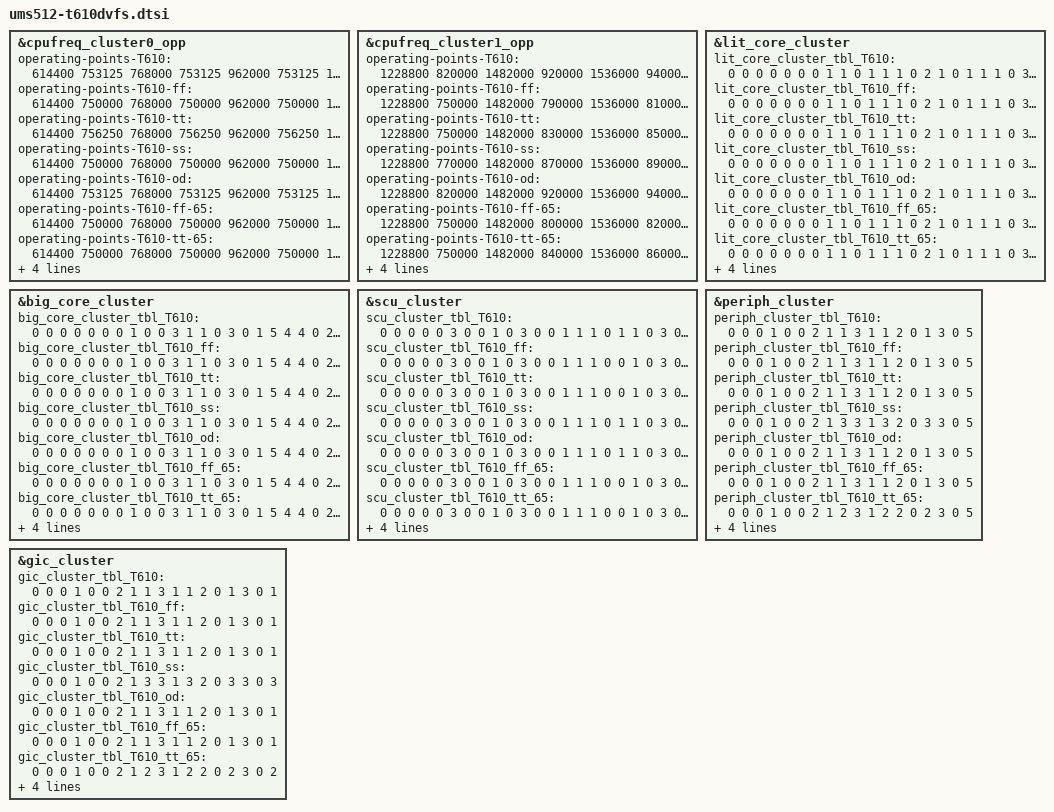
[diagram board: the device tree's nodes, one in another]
// SPDX-License-Identifier: (GPL-2.0+ OR MIT)
/*
 * Unisoc Sharkl5Pro platform T610 SOC DVFS DTS file
 *
 * Copyright (C) 2019, Unisoc Communications Inc.
 */

#include "sharkl5Pro.dtsi"
#include "ums512.dtsi"

&cpufreq_cluster0_opp {
	/* operating-points-T610-0-0
	 * v0/v1-soc_ver 0-binning 0-temp
	 * v0-T618 v1-T610
	 */
	operating-points-T610 = <
		/* kHZ   uV */
		614400  753125
		768000  753125
		962000  753125
		1144000 815625
		1228800 846875
		1482000 934375
		1536000 953125
		1716000 1015625
		1820000 1050000
	>;

	operating-points-T610-ff = <
		/* kHZ   uV */
		614400  750000
		768000  750000
		962000  750000
		1144000 750000
		1228800 750000
		1482000 803125
		1536000 821875
		1716000 884375
		1820000 921875
	>;

	operating-points-T610-tt = <
		/* kHZ   uV */
		614400  756250
		768000  756250
		962000  756250
		1144000 756250
		1228800 756250
		1482000 843750
		1536000 862500
		1716000 925000
		1820000 962500
	>;

	operating-points-T610-ss = <
		/* kHZ   uV */
		614400  750000
		768000  750000
		962000  750000
		1144000 765625
		1228800 796875
		1482000 884375
		1536000 903125
		1716000 965625
		1820000 1000000
	>;

	operating-points-T610-od = <
		/* kHZ   uV */
		614400  753125
		768000  753125
		962000  753125
		1144000 815625
		1228800 846875
		1482000 934375
		1536000 953125
		1716000 1015625
		1820000 1050000
	>;

	operating-points-T610-ff-65 = <
		/* kHZ   uV */
		614400  750000
		768000  750000
		962000  750000
		1144000 750000
		1228800 750000
		1482000 812500
		1536000 834375
		1716000 903125
		1820000 940625
	>;

	operating-points-T610-tt-65 = <
		/* kHZ   uV */
		614400  750000
		768000  750000
		962000  750000
		1144000 750000
		1228800 759375
		1482000 856250
		1536000 875000
		1716000 943750
		1820000 981250
	>;

	operating-points-T610-ss-65 = <
		/* kHZ   uV */
		614400  750000
		768000  750000
		962000  750000
		1144000 771875
		1228800 803125
		1482000 896875
		1536000 915625
		1716000 984375
		1820000 1021875
	>;

	operating-points-T610-od-65 = <
		/* kHZ   uV */
		614400  756250
		768000  756250
		962000  756250
		1144000 821875
		1228800 853125
		1482000 946875
		1536000 965625
		1716000 1034375
	>;
};

&cpufreq_cluster1_opp {
	operating-points-T610 = <
		/* kHZ   uV */
		1228800	 820000
		1482000	 920000
		1536000	 940000
		1742000  1020000
		1820000  1050000
	>;

	operating-points-T610-ff = <
		/* kHZ   uV */
		1228800	 750000
		1482000	 790000
		1536000	 810000
		1742000  890000
		1820000  920000
	>;

	operating-points-T610-tt = <
		/* kHZ   uV */
		1228800	 750000
		1482000	 830000
		1536000	 850000
		1742000  930000
		1820000  960000
	>;

	operating-points-T610-ss = <
		/* kHZ   uV */
		1228800	 770000
		1482000	 870000
		1536000	 890000
		1742000  970000
		1820000  1000000
	>;

	operating-points-T610-od = <
		/* kHZ   uV */
		1228800	 820000
		1482000	 920000
		1536000	 940000
		1742000  1020000
		1820000  1050000
	>;

	operating-points-T610-ff-65 = <
		/* kHZ   uV */
		1228800	 750000
		1482000	 800000
		1536000	 820000
		1742000  910000
		1820000  940000
	>;

	operating-points-T610-tt-65 = <
		/* kHZ   uV */
		1228800	 750000
		1482000	 840000
		1536000	 860000
		1742000  950000
		1820000  980000
	>;

	operating-points-T610-ss-65 = <
		/* kHZ   uV */
		1228800	 770000
		1482000	 880000
		1536000	 900000
		1742000  990000
		1820000  1020000
	>;

	operating-points-T610-od-65 = <
		/* kHZ   uV */
		1228800	 830000
		1482000	 930000
		1536000	 960000
		1742000  1040000
	>;
};

&lit_core_cluster{
	/* lit-core-dvfs-tbl-v1-0-0
	 * v0/v1-soc_ver v0-T618 v1-T610 0-binning 0-temp
	 * sel, div, vol, vote_scu, vote_peri, vote_gic, mpllx
	 */
	lit_core_cluster_tbl_T610 = <
		0 0 0 0 0 0 0
		1 1 0 1 1 1 0
		2 1 0 1 1 1 0
		3 0 0 2 1 1 0
		3 0 1 3 1 1 1
		1 0 2 4 1 1 0
		3 0 3 5 4 4 2
		2 0 4 6 4 4 0
		3 0 5 7 4 5 3
		3 0 6 8 4 5 4
		3 0 6 8 4 5 4
	>;

	lit_core_cluster_tbl_T610_ff = <
		0 0 0 0 0 0 0
		1 1 0 1 1 1 0
		2 1 0 1 1 1 0
		3 0 0 2 1 1 0
		3 0 0 3 1 1 1
		1 0 0 4 1 1 0
		3 0 1 5 4 4 2
		2 0 2 6 4 4 0
		3 0 3 7 4 5 3
		3 0 4 8 4 5 4
		3 0 4 8 4 5 4
	>;

	lit_core_cluster_tbl_T610_tt = <
		0 0 0 0 0 0 0
		1 1 0 1 1 1 0
		2 1 0 1 1 1 0
		3 0 0 2 1 1 0
		3 0 0 3 1 1 1
		1 0 0 4 1 1 0
		3 0 1 5 4 4 2
		2 0 2 6 4 4 0
		3 0 3 7 4 5 3
		3 0 4 8 4 5 4
		3 0 4 8 4 5 4
	>;

	lit_core_cluster_tbl_T610_ss = <
		0 0 0 0 0 0 0
		1 1 0 1 1 1 0
		2 1 0 1 1 1 0
		3 0 0 2 1 1 0
		3 0 1 3 1 1 1
		1 0 2 4 1 1 0
		3 0 3 5 4 4 2
		2 0 4 6 4 4 0
		3 0 5 7 4 5 3
		3 0 6 8 4 5 4
		3 0 6 8 4 5 4
	>;

	lit_core_cluster_tbl_T610_od = <
		0 0 0 0 0 0 0
		1 1 0 1 1 1 0
		2 1 0 1 1 1 0
		3 0 0 2 1 1 0
		3 0 1 3 1 1 1
		1 0 2 4 1 1 0
		3 0 3 5 4 4 2
		2 0 4 6 4 4 0
		3 0 5 7 4 5 3
		3 0 6 8 4 5 4
		3 0 6 8 4 5 4
	>;

	lit_core_cluster_tbl_T610_ff_65 = <
		0 0 0 0 0 0 0
		1 1 0 1 1 1 0
		2 1 0 1 1 1 0
		3 0 0 2 1 1 0
		3 0 0 3 1 1 1
		1 0 0 4 1 1 0
		3 0 1 5 4 4 2
		2 0 2 6 4 4 0
		3 0 3 7 4 5 3
		3 0 4 8 4 5 4
		3 0 4 8 4 5 4
	>;

	lit_core_cluster_tbl_T610_tt_65 = <
		0 0 0 0 0 0 0
		1 1 0 1 1 1 0
		2 1 0 1 1 1 0
		3 0 0 2 1 1 0
		3 0 0 3 1 1 1
		1 0 1 4 1 1 0
		3 0 2 5 4 4 2
		2 0 3 6 4 4 0
		3 0 4 7 4 5 3
		3 0 5 8 4 5 4
		3 0 5 8 4 5 4
	>;

	lit_core_cluster_tbl_T610_ss_65 = <
		0 0 0 0 0 0 0
		1 1 0 1 1 1 0
		2 1 0 1 1 1 0
		3 0 0 2 1 1 0
		3 0 1 3 1 1 1
		1 0 2 4 1 1 0
		3 0 3 5 4 4 2
		2 0 4 6 4 4 0
		3 0 5 7 4 5 3
		3 0 6 8 4 5 4
		3 0 6 8 4 5 4
	>;

	lit_core_cluster_tbl_T610_od_65 = <
		0 0 0 0 0 0 0
		1 1 0 1 1 1 0
		2 1 0 1 1 1 0
		3 0 0 2 1 1 0
		3 0 1 3 1 1 1
		1 0 2 4 1 1 0
		3 0 3 5 4 4 2
		2 0 4 6 4 4 0
		3 0 5 7 4 5 3
		3 0 5 7 4 5 3
		3 0 5 7 4 5 3
	>;
};

&big_core_cluster {
	/* sel, div, vol, vote_scu, vote_peri, vote_gic, mpllx */
	big_core_cluster_tbl_T610 = <
		0 0 0 0 0 0 0
		1 0 0 3 1 1 0
		3 0 1 5 4 4 0
		2 0 2 6 4 4 0
		3 0 3 7 4 5 1
		3 0 4 8 4 5 2
		3 0 4 8 4 5 2
	>;

	big_core_cluster_tbl_T610_ff = <
		0 0 0 0 0 0 0
		1 0 0 3 1 1 0
		3 0 1 5 4 4 0
		2 0 2 6 4 4 0
		3 0 3 7 4 5 1
		3 0 4 8 4 5 2
		3 0 4 8 4 5 2
	>;

	big_core_cluster_tbl_T610_tt = <
		0 0 0 0 0 0 0
		1 0 0 3 1 1 0
		3 0 1 5 4 4 0
		2 0 2 6 4 4 0
		3 0 3 7 4 5 1
		3 0 4 8 4 5 2
		3 0 4 8 4 5 2
	>;

	big_core_cluster_tbl_T610_ss = <
		0 0 0 0 0 0 0
		1 0 0 3 1 1 0
		3 0 1 5 4 4 0
		2 0 2 6 4 4 0
		3 0 3 7 4 5 1
		3 0 4 8 4 5 2
		3 0 4 8 4 5 2
	>;

	big_core_cluster_tbl_T610_od = <
		0 0 0 0 0 0 0
		1 0 0 3 1 1 0
		3 0 1 5 4 4 0
		2 0 2 6 4 4 0
		3 0 3 7 4 5 1
		3 0 4 8 4 5 2
		3 0 4 8 4 5 2
	>;

	big_core_cluster_tbl_T610_ff_65 = <
		0 0 0 0 0 0 0
		1 0 0 3 1 1 0
		3 0 1 5 4 4 0
		2 0 2 6 4 4 0
		3 0 3 7 4 5 1
		3 0 4 8 4 5 2
		3 0 4 8 4 5 2
	>;

	big_core_cluster_tbl_T610_tt_65 = <
		0 0 0 0 0 0 0
		1 0 0 3 1 1 0
		3 0 1 5 4 4 0
		2 0 2 6 4 4 0
		3 0 3 7 4 5 1
		3 0 4 8 4 5 2
		3 0 4 8 4 5 2
	>;

	big_core_cluster_tbl_T610_ss_65 = <
		0 0 0 0 0 0 0
		1 0 0 3 1 1 0
		3 0 1 5 4 4 0
		2 0 2 6 4 4 0
		3 0 3 7 4 5 1
		3 0 4 8 4 5 2
		3 0 4 8 4 5 2
	>;

	big_core_cluster_tbl_T610_od_65 = <
		0 0 0 0 0 0 0
		1 0 0 3 1 1 0
		3 0 1 5 4 4 0
		2 0 2 6 4 4 0
		3 0 3 7 4 5 1
		3 0 3 7 4 5 1
		3 0 3 7 4 5 1
	>;
};

&scu_cluster {
	/* sel div vol ace_div mpllx */
	scu_cluster_tbl_T610 = <
		0 0 0 0 0
		3 0 0 1 0
		3 0 0 1 1
		1 0 1 1 0
		3 0 2 1 2
		3 0 3 1 3
		3 0 4 1 4
		3 0 5 1 5
		3 0 6 1 6
		3 0 6 1 6
	>;

	scu_cluster_tbl_T610_ff = <
		0 0 0 0 0
		3 0 0 1 0
		3 0 0 1 1
		1 0 0 1 0
		3 0 0 1 2
		3 0 1 1 3
		3 0 2 1 4
		3 0 3 1 5
		3 0 4 1 6
		3 0 4 1 6
	>;

	scu_cluster_tbl_T610_tt = <
		0 0 0 0 0
		3 0 0 1 0
		3 0 0 1 1
		1 0 0 1 0
		3 0 0 1 2
		3 0 1 1 3
		3 0 2 1 4
		3 0 3 1 5
		3 0 4 1 6
		3 0 4 1 6
	>;

	scu_cluster_tbl_T610_ss = <
		0 0 0 0 0
		3 0 0 1 0
		3 0 0 1 1
		1 0 1 1 0
		3 0 2 1 2
		3 0 3 1 3
		3 0 4 1 4
		3 0 5 1 5
		3 0 6 1 6
		3 0 6 1 6
	>;

	scu_cluster_tbl_T610_od = <
		0 0 0 0 0
		3 0 0 1 0
		3 0 0 1 1
		1 0 1 1 0
		3 0 2 1 2
		3 0 3 1 3
		3 0 4 1 4
		3 0 5 1 5
		3 0 6 1 6
		3 0 6 1 6
	>;

	scu_cluster_tbl_T610_ff_65 = <
		0 0 0 0 0
		3 0 0 1 0
		3 0 0 1 1
		1 0 0 1 0
		3 0 0 1 2
		3 0 1 1 3
		3 0 2 1 4
		3 0 3 1 5
		3 0 4 1 6
		3 0 4 1 6
	>;

	scu_cluster_tbl_T610_tt_65 = <
		0 0 0 0 0
		3 0 0 1 0
		3 0 0 1 1
		1 0 0 1 0
		3 0 1 1 2
		3 0 2 1 3
		3 0 3 1 4
		3 0 4 1 5
		3 0 5 1 6
		3 0 5 1 6
	>;

	scu_cluster_tbl_T610_ss_65 = <
		0 0 0 0 0
		3 0 0 1 0
		3 0 0 1 1
		1 0 1 1 0
		3 0 2 1 2
		3 0 3 1 3
		3 0 4 1 4
		3 0 5 1 5
		3 0 6 1 6
		3 0 6 1 6
	>;

	scu_cluster_tbl_T610_od_65 = <
		0 0 0 0 0
		3 0 0 1 0
		3 0 0 1 1
		1 0 1 1 0
		3 0 2 1 2
		3 0 3 1 3
		3 0 4 1 4
		3 0 5 1 5
		3 0 5 1 5
		3 0 5 1 5
	>;
};

&periph_cluster{
	/* sel div vol */
	periph_cluster_tbl_T610 = <
		0 0 0
		1 0 0
		2 1 1
		3 1 1
		2 0 1
		3 0 5
	>;

	periph_cluster_tbl_T610_ff = <
		0 0 0
		1 0 0
		2 1 1
		3 1 1
		2 0 1
		3 0 5
	>;

	periph_cluster_tbl_T610_tt = <
		0 0 0
		1 0 0
		2 1 1
		3 1 1
		2 0 1
		3 0 5
	>;

	periph_cluster_tbl_T610_ss = <
		0 0 0
		1 0 0
		2 1 3
		3 1 3
		2 0 3
		3 0 5
	>;

	periph_cluster_tbl_T610_od = <
		0 0 0
		1 0 0
		2 1 1
		3 1 1
		2 0 1
		3 0 5
	>;

	periph_cluster_tbl_T610_ff_65 = <
		0 0 0
		1 0 0
		2 1 1
		3 1 1
		2 0 1
		3 0 5
	>;

	periph_cluster_tbl_T610_tt_65 = <
		0 0 0
		1 0 0
		2 1 2
		3 1 2
		2 0 2
		3 0 5
	>;

	periph_cluster_tbl_T610_ss_65 = <
		0 0 0
		1 0 0
		2 1 2
		3 1 2
		2 0 2
		3 0 5
	>;

	periph_cluster_tbl_T610_od_65 = <
		0 0 0
		1 0 0
		2 1 1
		3 1 1
		2 0 1
		3 0 5
	>;
};

&gic_cluster {
	/*sel div vol*/
	gic_cluster_tbl_T610 = <
		0 0 0
		1 0 0
		2 1 1
		3 1 1
		2 0 1
		3 0 1
	>;

	gic_cluster_tbl_T610_ff = <
		0 0 0
		1 0 0
		2 1 1
		3 1 1
		2 0 1
		3 0 1
	>;

	gic_cluster_tbl_T610_tt = <
		0 0 0
		1 0 0
		2 1 1
		3 1 1
		2 0 1
		3 0 1
	>;

	gic_cluster_tbl_T610_ss = <
		0 0 0
		1 0 0
		2 1 3
		3 1 3
		2 0 3
		3 0 3
	>;

	gic_cluster_tbl_T610_od = <
		0 0 0
		1 0 0
		2 1 1
		3 1 1
		2 0 1
		3 0 1
	>;

	gic_cluster_tbl_T610_ff_65 = <
		0 0 0
		1 0 0
		2 1 1
		3 1 1
		2 0 1
		3 0 1
	>;

	gic_cluster_tbl_T610_tt_65 = <
		0 0 0
		1 0 0
		2 1 2
		3 1 2
		2 0 2
		3 0 2
	>;

	gic_cluster_tbl_T610_ss_65 = <
		0 0 0
		1 0 0
		2 1 2
		3 1 2
		2 0 2
		3 0 2
	>;

	gic_cluster_tbl_T610_od_65 = <
		0 0 0
		1 0 0
		2 1 1
		3 1 1
		2 0 1
		3 0 1
	>;
};
